# HDSC_HC32F120F8TA register map
Vendor: HDSC Co.,Ltd.; Series: ARMCM0P; File version: 1.0
CPU: CM0P r0p1, little endian, no MPU, no FPU, 4 interrupt priority bits
Registers are 32-bit, read-write, reset 0x0 unless marked. A register's access mark holds for its fields unless they carry their own. Offsets are from the block's base; lines under a group give offsets from that group; [hi:lo] are bit positions; {n}, {i} and the like mark numbered series; 'fields as' and 'values as' point back to an identical list; <NAME> marks a mode.

## Memory map
0x000000C0 ICG size 0x20
0x40000000 CTC size 0xC
0x40000800 EFM size 0x285
0x40000C00 AOS size 0x68
0x40001800 USART1 size 0x10 — desc USART
0x40001C00 USART2 size 0x10 — desc USART
0x40002000 USART3 size 0x10 — desc USART
0x40002400 USART4 size 0x10 — desc USART
0x40003800 SPI size 0x1C
0x40004800 I2C size 0x34
0x40005800 TMR0 size 0x18
{0x40007400+0x400*n} TMRB{n} size 0x144 (n=1..8) — desc TMRB
0x4000B800 ADC size 0xB1
0x4000CC00 SWDT size 0xC
0x4000D400 RTC size 0x40
0x40011000 INTC size 0x100
0x40013800 PORT size 0x5F
0x40014000 PWC size 0x41
0x40014100 RMU size 0x2
0x40014400 CMU size 0x3D
0x40015000 DBGC size 0x8
0x40015400 CRC size 0x100

## ADC
Base 0x4000B800
0x00 STR 8-bit
  [0] STRT
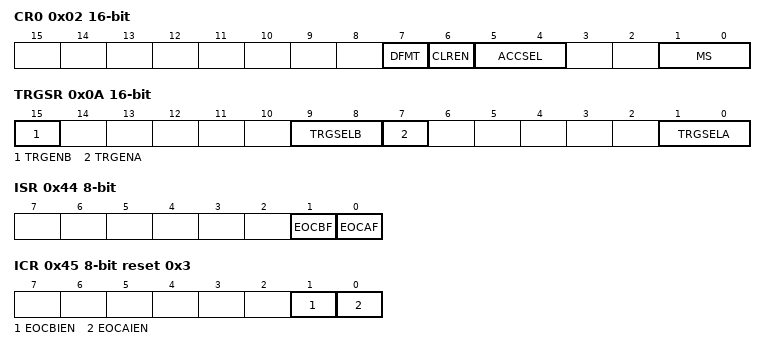
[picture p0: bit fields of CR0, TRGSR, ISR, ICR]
0x02 CR0 16-bit
  [7] DFMT, [6] CLREN, [5:4] ACCSEL, [1:0] MS
0x04 CR1 16-bit
  [2] RSCHSEL
0x0A TRGSR 16-bit
  [15] TRGENB, [9:8] TRGSELB, [7] TRGENA, [1:0] TRGSELA
0x0C CHSELRA0 16-bit
  [11:0] CHSELA
0x10 CHSELRB0 16-bit
  [11:0] CHSELB
0x18 EXCHSELR 8-bit
  [0] EXCHSEL
0x20 SSTR 8-bit reset 0xB
0x44 ISR 8-bit ro
  [1] EOCBF, [0] EOCAF
0x45 ICR 8-bit reset 0x3
  [1] EOCBIEN, [0] EOCAIEN
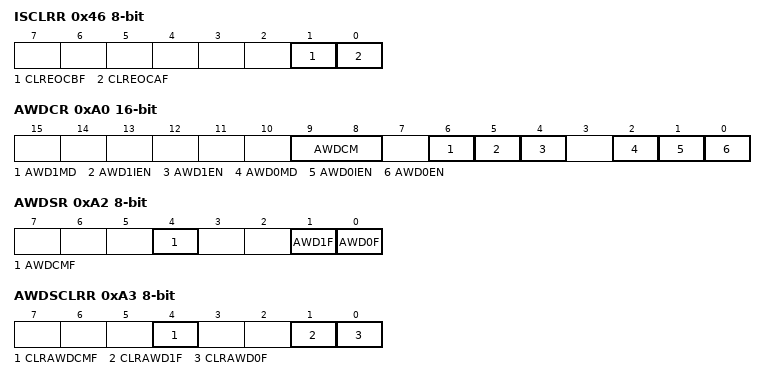
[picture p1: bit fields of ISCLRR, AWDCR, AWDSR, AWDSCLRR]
0x46 ISCLRR 8-bit wo
  [1] CLREOCBF, [0] CLREOCAF
{0x50+2i} DR{i} 16-bit ro (i=0..11)
0xA0 AWDCR 16-bit
  [9:8] AWDCM, [6] AWD1MD, [5] AWD1IEN, [4] AWD1EN, [2] AWD0MD, [1] AWD0IEN, [0] AWD0EN
0xA2 AWDSR 8-bit ro
  [4] AWDCMF, [1] AWD1F, [0] AWD0F
0xA3 AWDSCLRR 8-bit wo
  [4] CLRAWDCMF, [1] CLRAWD1F, [0] CLRAWD0F
0xA4 AWD0DR0 16-bit
0xA6 AWD0DR1 16-bit reset 0xFFFF
0xA8 AWD0CHSR 8-bit
  [4:0] AWDCH
0xAC AWD1DR0 16-bit
0xAE AWD1DR1 16-bit reset 0xFFFF
0xB0 AWD1CHSR 8-bit
  [4:0] AWDCH

## AOS
Base 0x40000C00
0x00 INTC_STRGCR wo
  [0] STRG
0x20 TMR0_HTSSR reset 0x7F
  [6:0] TRGSEL
0x50 TMRB_HTSSR reset 0x7F
  [6:0] TRGSEL
0x60 ADC_ITRGSELR0 reset 0x7F
  [6:0] TRGSEL
0x64 ADC_ITRGSELR1 reset 0x7F
  [6:0] TRGSEL

## CMU
Base 0x40014400
0x00 PERICKSEL 8-bit
  [2:0] PERICKSEL
0x04 XTALSTDSR 8-bit
  [0] XTALSTDF
0x08 SCKDIVR 8-bit
  [2:0] SCKDIV
0x0C CKSWR 8-bit
  [1:0] CKSW
0x10 XTALCR 8-bit reset 0x1
  [0] XTALSTP
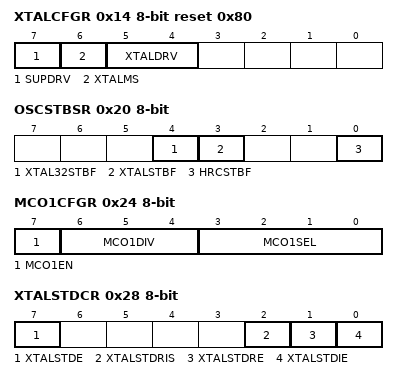
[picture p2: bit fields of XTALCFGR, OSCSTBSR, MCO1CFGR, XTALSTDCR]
0x14 XTALCFGR 8-bit reset 0x80
  [7] SUPDRV, [6] XTALMS, [5:4] XTALDRV
0x15 XTALSTBCR 8-bit
  [2:0] XTALSTB
0x18 HRCCR 8-bit
  [0] HRCSTP
0x20 OSCSTBSR 8-bit ro
  [4] XTAL32STBF, [3] XTALSTBF, [0] HRCSTBF
0x24 MCO1CFGR 8-bit
  [7] MCO1EN, [6:4] MCO1DIV, [3:0] MCO1SEL
0x28 XTALSTDCR 8-bit
  [7] XTALSTDE, [2] XTALSTDRIS, [1] XTALSTDRE, [0] XTALSTDIE
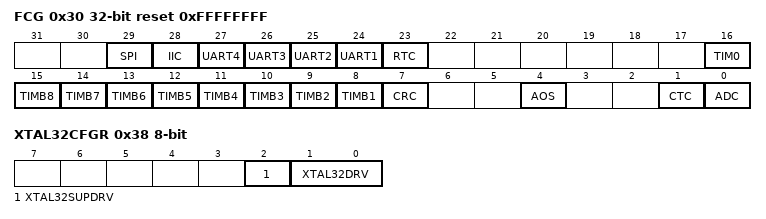
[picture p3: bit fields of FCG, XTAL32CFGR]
0x30 FCG reset 0xFFFFFFFF
  [29] SPI, [28] IIC, [n+23] UART{n} (n=1..4), [23] RTC, [16] TIM0, [n+7] TIMB{n} (n=1..8), [7] CRC, [4] AOS, [1] CTC, [0] ADC
0x34 XTAL32CR 8-bit reset 0x1
  [0] XTAL32STP
0x38 XTAL32CFGR 8-bit
  [2] XTAL32SUPDRV, [1:0] XTAL32DRV
0x39 XTAL32NFR 8-bit
  [1:0] XTAL32NF
0x3C LRCCR 8-bit
  [0] LRCSTP

## CRC
Base 0x40015400
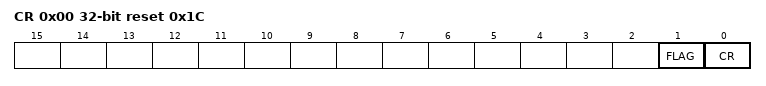
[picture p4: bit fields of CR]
0x00 CR reset 0x1C
  [1] FLAG, [0] CR
0x04 RESLT reset 0x7800
{0x80+4i} DAT{i} (i=0..31)

## CTC
Base 0x40000000
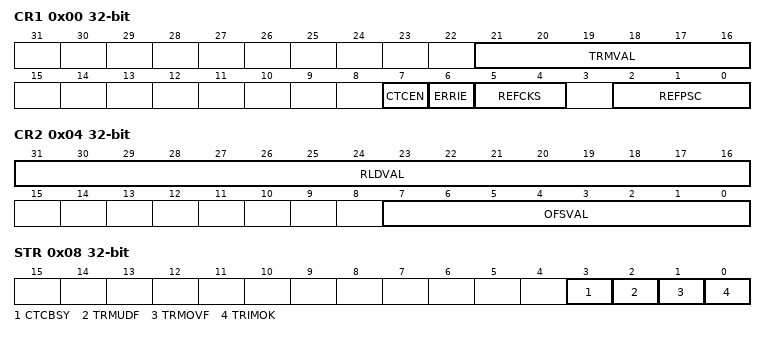
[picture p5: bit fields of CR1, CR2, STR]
0x00 CR1
  [21:16] TRMVAL, [7] CTCEN, [6] ERRIE, [5:4] REFCKS, [2:0] REFPSC
0x04 CR2
  [31:16] RLDVAL, [7:0] OFSVAL
0x08 STR ro
  [3] CTCBSY, [2] TRMUDF, [1] TRMOVF, [0] TRIMOK

## DBGC
Base 0x40015000
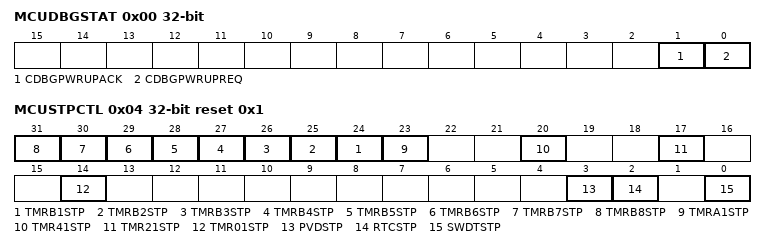
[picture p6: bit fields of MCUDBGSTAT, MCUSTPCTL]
0x00 MCUDBGSTAT
  [1] CDBGPWRUPACK, [0] CDBGPWRUPREQ
0x04 MCUSTPCTL reset 0x1
  [n+23] TMRB{n}STP (n=1..8), [23] TMRA1STP, [20] TMR41STP, [17] TMR21STP, [14] TMR01STP, [3] PVDSTP, [2] RTCSTP, [0] SWDTSTP

## EFM
Base 0x40000800
0x00 FAPRT
  [15:0] FAPRT
0x04 FSTP
  [0] FSTP
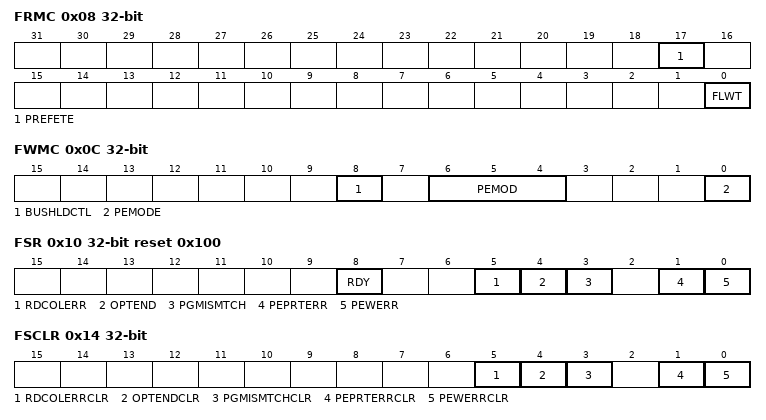
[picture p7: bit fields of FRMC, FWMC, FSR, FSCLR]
0x08 FRMC (reset mask 0x1)
  [17] PREFETE, [0] FLWT
0x0C FWMC
  [8] BUSHLDCTL, [6:4] PEMOD, [0] PEMODE
0x10 FSR ro reset 0x100
  [8] RDY, [5] RDCOLERR, [4] OPTEND, [3] PGMISMTCH, [1] PEPRTERR, [0] PEWERR
0x14 FSCLR
  [5] RDCOLERRCLR, [4] OPTENDCLR, [3] PGMISMTCHCLR, [1] PEPRTERRCLR, [0] PEWERRCLR
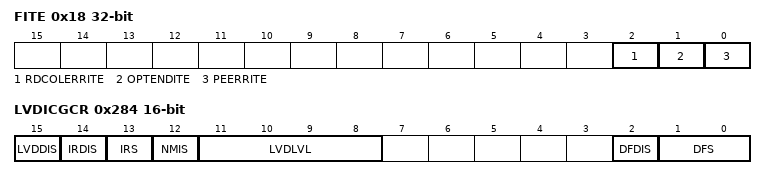
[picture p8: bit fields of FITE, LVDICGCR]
0x18 FITE
  [2] RDCOLERRITE, [1] OPTENDITE, [0] PEERRITE
0x20 FPMTSW
  [15:0] FPMTSW
0x24 FPMTEW
  [15:0] FPMTEW
{0x50+4i} UQID{i} ro (i=0..2)
0x282 HRCCFGR 8-bit
  [3:0] HRCFREQS
0x284 LVDICGCR 16-bit reset not defined
  [15] LVDDIS, [14] IRDIS, [13] IRS, [12] NMIS, [11:8] LVDLVL, [2] DFDIS, [1:0] DFS
